# cc13x2_cc26x2 register map
File version: 2.1
CPU: CM4 r0p1, little endian, MPU, FPU, 3 interrupt priority bits
Registers are 32-bit, read-write, reset 0x0 unless marked. A register's access mark holds for its fields unless they carry their own. Offsets are from the block's base; [hi:lo] are bit positions; {n}, {i} and the like mark numbered series; 'fields as' and 'values as' point back to an identical list.

## CRYPTO — DMA Crypto Core is a low power low gate count crypto core with DMA capability and local key storage.
Base 0x40024000
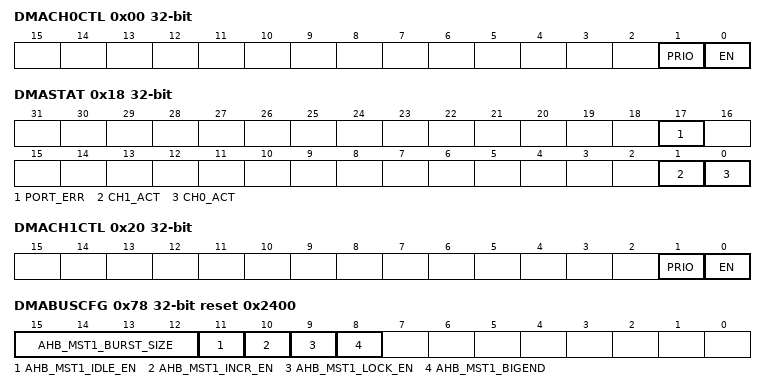
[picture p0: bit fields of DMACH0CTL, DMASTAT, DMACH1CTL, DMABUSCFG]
0x00 DMACH0CTL — Channel 0 Control his register is used for channel enabling and priority selection. When a channel is disabled, it becomes inactive only when all ongoing requests are finished.
  [1] PRIO, [0] EN
0x04 DMACH0EXTADDR — Channel 0 External Address
  [31:0] ADDR
0x0C DMACH0LEN — Channel 0 DMA Length
  [15:0] DMALEN
0x18 DMASTAT ro — DMAC Status his register provides the actual state of each DMA channel. It also reports port errors in case these were received by the master interface module during the data transfer.
  [17] PORT_ERR, [1] CH1_ACT, [0] CH0_ACT
0x1C DMASWRESET wo — DMAC Software Reset oftware reset is used to reset the DMAC to stop all transfers and clears the port error status register. After the software reset is performed, all the channels are disabled and no new requests are performed by the channels. The DMAC waits for the existing (active) requests to finish and accordingly sets the DMASTAT.
  [0] SWRES
0x20 DMACH1CTL — Channel 1 Control his register is used for channel enabling and priority selection. When a channel is disabled, it becomes inactive only when all ongoing requests are finished.
  [1] PRIO, [0] EN
0x24 DMACH1EXTADDR — Channel 1 External Address
  [31:0] ADDR
0x2C DMACH1LEN — Channel 1 DMA Length
  [15:0] DMALEN
0x78 DMABUSCFG reset 0x2400 — DMAC Master Run-time Parameters his register defines all the run-time parameters for the AHB master interface port. These parameters are required for the proper functioning of the EIP-101m AHB master adapter.
  [15:12] AHB_MST1_BURST_SIZE, [11] AHB_MST1_IDLE_EN, [10] AHB_MST1_INCR_EN, [9] AHB_MST1_LOCK_EN, [8] AHB_MST1_BIGEND
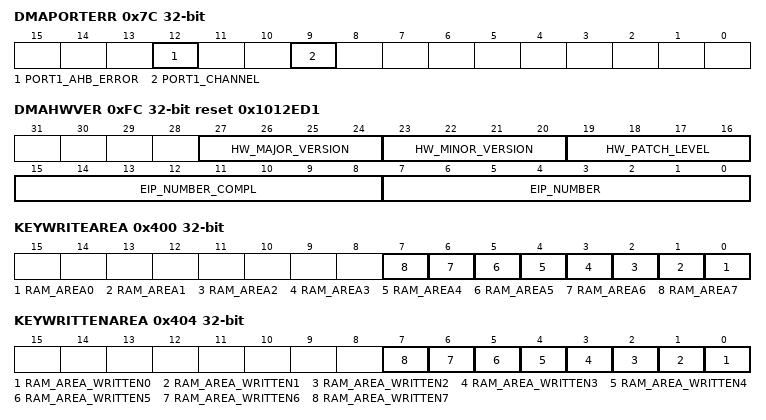
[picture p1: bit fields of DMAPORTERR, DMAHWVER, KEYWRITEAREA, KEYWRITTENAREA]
0x7C DMAPORTERR ro — DMAC Port Error Raw Status his register provides the actual status of individual port errors. It also indicates which channel is serviced by an external AHB port (which is frozen by a port error). A port error aborts operations on all serviced channels (channel enable bit is forced to 0) and prevents further transfers via that port until the error is cleared by writing to the DMASWRESET register.
  [12] PORT1_AHB_ERROR, [9] PORT1_CHANNEL
0xFC DMAHWVER ro reset 0x1012ED1 — DMAC Version his register contains an indication (or signature) of the EIP type of this DMAC, as well as the hardware version/patch numbers.
  [27:24] HW_MAJOR_VERSION, [23:20] HW_MINOR_VERSION, [19:16] HW_PATCH_LEVEL, [15:8] EIP_NUMBER_COMPL, [7:0] EIP_NUMBER
0x400 KEYWRITEAREA — Key Store Write Area his register defines where the keys should be written in the key store RAM. After writing this register, the key store module is ready to receive the keys through a DMA operation. In case the key data transfer triggered an error in the key store, the error will be available in the interrupt status register after the DMA is finished. The key store write-error is asserted when the programmed/selected area is not completely written. This error is also asserted when the DMA operation writes to ram areas that are not selected. he key store RAM is divided into 8 areas of 128 bits. 92-bit keys written in the key store RAM should start on boundaries of 256 bits. This means that writing a 192-bit key to the key store RAM must be done by writing 256 bits of data with the 64 most-significant bits set to 0. These bits are ignored by the AES engine.
  [n] RAM_AREA{n} (n=0..7)
0x404 KEYWRITTENAREA — Key Store Written Area his register shows which areas of the key store RAM contain valid written keys. hen a new key needs to be written to the key store, on a location that is already occupied by a valid key, this key area must be cleared first. This can be done by writing this register before the new key is written to the key store memory. ttempting to write to a key area that already contains a valid key is not allowed and results in an error.
  [n] RAM_AREA_WRITTEN{n} write-1-clears (n=0..7)
0x408 KEYSIZE reset 0x1 — Key Store Size his register defines the size of the keys that are written with DMA. This register should be configured before writing to the KEY_STORE_WRITE_AREA register.
  [1:0] SIZE
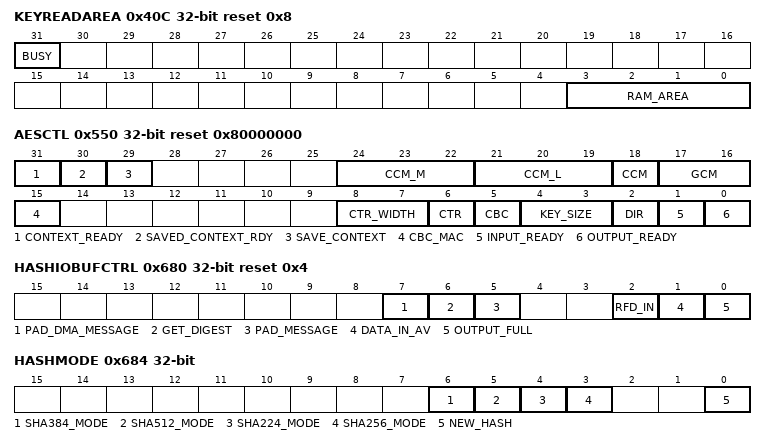
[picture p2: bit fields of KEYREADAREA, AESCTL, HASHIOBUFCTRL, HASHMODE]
0x40C KEYREADAREA reset 0x8 — Key Store Read Area his register selects the key store RAM area from where the key needs to be read that will be used for an AES operation. The operation directly starts after writing this register. When the operation is finished, the status of the key store read operation is available in the interrupt status register. Key store read error is asserted when a RAM area is selected which does not contain valid written key.
  [31] BUSY, [3:0] RAM_AREA
{0x500+4i} AESKEY2{i} (i=0..3) wo — AES_KEY2_0 / AES_GHASH_H_IN_0 econd Key / GHASH Key (internal, but clearable) he following registers are not accessible through the host for reading and writing. They are used to store internally calculated key information and intermediate results. However, when the host performs a write to the any of the respective AES_KEY2_n or AES_KEY3_n addresses, respectively the whole 128-bit AES_KEY2_n or AES_KEY3_n register is cleared to 0s. he AES_GHASH_H_IN_n registers (required for GHASH, which is part of GCM) are mapped to the AES_KEY2_n registers. The (intermediate) authentication result for GCM and CCM is stored in the AES_KEY3_n register.
  [31:0] AES_KEY2
{0x510+4i} AESKEY3{i} (i=0..3) wo — AES_KEY3_0 / AES_KEY2_4 hird Key / Second Key (internal, but clearable) he following registers are not accessible through the host for reading and writing. They are used to store internally calculated key information and intermediate results. However, when the host performs a write to the any of the respective AES_KEY2_n or AES_KEY3_n addresses, respectively the whole 128-bit AES_KEY2_n or AES_KEY3_n register is cleared to 0s. he AES_GHASH_H_IN_n registers (required for GHASH, which is part of GCM) are mapped to the AES_KEY2_n registers. The (intermediate) authentication result for GCM and CCM is stored in the AES_KEY3_n register.
  [31:0] AES_KEY3
{0x540+4i} AESIV{i} (i=0..3) — AES initialization vector registers hese registers are used to provide and read the IV from the AES engine.
  [31:0] AES_IV
0x550 AESCTL reset 0x80000000 — AES Control ES input/output buffer control and mode register his register specifies the AES mode of operation for the EIP-120t. lectronic codebook (ECB) mode is automatically selected if bits [28:5] of this register are all 0.
  [31] CONTEXT_READY, [30] SAVED_CONTEXT_RDY, [29] SAVE_CONTEXT, [24:22] CCM_M, [21:19] CCM_L, [18] CCM, [17:16] GCM, [15] CBC_MAC, [8:7] CTR_WIDTH, [6] CTR, [5] CBC, [4:3] KEY_SIZE, [2] DIR, [1] INPUT_READY, [0] OUTPUT_READY
0x554 AESDATALEN0 wo — AES Crypto Length 0 (LSW) hese registers are used to write the Length values to the EIP-120t. While processing, the length values decrement to 0. If both lengths are 0, the data stream is finished and a new context is requested. For basic AES modes (ECB, CBC, and CTR), a crypto length of 0 can be written if multiple streams need to be processed with the same key. Writing 0 length results in continued data requests until a new context is written. For the other modes (CBC-MAC, GCM, and CCM) no (new) data requests are done if the length decrements to or equals 0. t is advised to write a new length per packet. If the length registers decrement to 0, no new data is processed until a new context or length value is written. hen writing a new mode without writing the length registers, the length register values from the previous context is reused.
  [31:0] C_LENGTH
0x558 AESDATALEN1 wo — AES Crypto Length 1 (MSW) hese registers are used to write the Length values to the EIP-120t. While processing, the length values decrement to 0. If both lengths are 0, the data stream is finished and a new context is requested. For basic AES modes (ECB, CBC, and CTR), a crypto length of 0 can be written if multiple streams need to be processed with the same key. Writing 0 length results in continued data requests until a new context is written. For the other modes (CBC-MAC, GCM and CCM) no (new) data requests are done if the length decrements to or equals 0. t is advised to write a new length per packet. If the length registers decrement to 0, no new data is processed until a new context or length value is written. hen writing a new mode without writing the length registers, the length register values from the previous context is reused.
  [28:0] C_LENGTH
0x55C AESAUTHLEN wo — AES Authentication Length
  [31:0] AUTH_LENGTH
{0x560+4i} AESDATAOUT{i} ro (i=0..3) — Data Input/Output
  [31:0] DATA
0x560 AESDATAIN0 wo — AES Data Input_Output 0 he data registers are typically accessed through the DMA and not with host writes and/or reads. However, for debugging purposes the data input/output registers can be accessed via host write and read operations. The registers are used to buffer the input/output data blocks to/from the EIP-120t. ote: The data input buffer (AES_DATA_IN_n) and data output buffer (AES_DATA_OUT_n) are mapped to the same address locations. rites (both DMA and host) to these addresses load the Input Buffer while reads pull from the Output Buffer. Therefore, for write access, the data input buffer is written; for read access, the data output buffer is read. The data input buffer must be written before starting an operation. The data output buffer contains valid data on completion of an operation. Therefore, any 128-bit data block can be split over multiple 32-bit word transfers; these can be mixed with other host transfers over the external interface.
  [31:0] AES_DATA_IN_OUT
0x564 AESDATAIN1 wo — AES Data Input_Output 0 he data registers are typically accessed through the DMA and not with host writes and/or reads. However, for debugging purposes the data input/output registers can be accessed via host write and read operations. The registers are used to buffer the input/output data blocks to/from the EIP-120t. ote: The data input buffer (AES_DATA_IN_n) and data output buffer (AES_DATA_OUT_n) are mapped to the same address locations. rites (both DMA and host) to these addresses load the Input Buffer while reads pull from the Output Buffer. Therefore, for write access, the data input buffer is written; for read access, the data output buffer is read. The data input buffer must be written before starting an operation. The data output buffer contains valid data on completion of an operation. Therefore, any 128-bit data block can be split over multiple 32-bit word transfers; these can be mixed with other host transfers over the external interface.
  [31:0] AES_DATA_IN_OUT
0x568 AESDATAIN2 wo — AES Data Input_Output 2 he data registers are typically accessed via DMA and not with host writes and/or reads. However, for debugging purposes the Data Input/Output Registers can be accessed via host write and read operations. The registers are used to buffer the input/output data blocks to/from the EIP-120t. ote: The data input buffer (AES_DATA_IN_n) and data output buffer (AES_DATA_OUT_n) are mapped to the same address locations. rites (both DMA and host) to these addresses load the Input Buffer while reads pull from the Output Buffer. Therefore, for write access, the data input buffer is written; for read access, the data output buffer is read. The data input buffer must be written before starting an operation. The data output buffer contains valid data on completion of an operation. Therefore, any 128-bit data block can be split over multiple 32-bit word transfers; these can be mixed with other host transfers over the external interface.
  [31:0] AES_DATA_IN_OUT
0x56C AESDATAIN3 wo — AES Data Input_Output 3 he data registers are typically accessed via DMA and not with host writes and/or reads. However, for debugging purposes the Data Input/Output Registers can be accessed via host write and read operations. The registers are used to buffer the input/output data blocks to/from the EIP-120t. ote: The data input buffer (AES_DATA_IN_n) and data output buffer (AES_DATA_OUT_n) are mapped to the same address locations. rites (both DMA and host) to these addresses load the Input Buffer while reads pull from the Output Buffer. Therefore, for write access, the data input buffer is written; for read access, the data output buffer is read. The data input buffer must be written before starting an operation. The data output buffer contains valid data on completion of an operation. Therefore, any 128-bit data block can be split over multiple 32-bit word transfers; these can be mixed with other host transfers over the external interface.
  [31:0] AES_DATA_IN_OUT
{0x570+4i} AESTAGOUT{i} (i=0..3) ro — AES Tag Out 0 he tag registers can be accessed via DMA or directly with host reads. hese registers buffer the TAG from the EIP-120t. The registers are shared with the intermediate authentication result registers, but cannot be read until the processing is finished. While processing, a read from these registers returns 0s. If an operation does not return a TAG, reading from these registers returns an IV. If an operation returns a TAG plus an IV and both need to be read by the host, the host must first read the TAG followed by the IV. Reading these in reverse order will return the IV twice.
  [31:0] AES_TAG
{0x600+4i} HASHDATAIN{i} wo (i=1..31) — HASH Data Input {i} he data input registers should be used to provide input data to the hash module through the slave interface.
  [31:0] HASH_DATA_IN
0x680 HASHIOBUFCTRL reset 0x4 — HASH Input_Output Buffer Control his register pair shares a single address location and contains bits that control and monitor the data flow between the host and the hash engine.
  [7] PAD_DMA_MESSAGE, [6] GET_DIGEST, [5] PAD_MESSAGE, [2] RFD_IN, [1] DATA_IN_AV, [0] OUTPUT_FULL
0x684 HASHMODE wo
  [6] SHA384_MODE, [5] SHA512_MODE, [4] SHA224_MODE, [3] SHA256_MODE, [0] NEW_HASH
0x688 HASHINLENL wo — HASH Input Length LSB
  [31:0] LENGTH_IN
0x68C HASHINLENH wo — HASH Input Length MSB
  [31:0] LENGTH_IN
0x6C0 HASHDIGESTA — HASH Digest A he hash digest registers consist of eight 32-bit registers, named HASH_DIGEST_A to HASH_DIGEST_H. After processing a message, the output digest can be read from these registers. These registers can be written with an intermediate hash result for continued hash operations.
  [31:0] HASH_DIGEST
0x6C4 HASHDIGESTB — HASH Digest B he hash digest registers consist of eight 32-bit registers, named HASH_DIGEST_A to HASH_DIGEST_H. After processing a message, the output digest can be read from these registers. These registers can be written with an intermediate hash result for continued hash operations.
  [31:0] HASH_DIGEST
0x6C8 HASHDIGESTC — HASH Digest C he hash digest registers consist of eight 32-bit registers, named HASH_DIGEST_A to HASH_DIGEST_H. After processing a message, the output digest can be read from these registers. These registers can be written with an intermediate hash result for continued hash operations.
  [31:0] HASH_DIGEST
0x6CC HASHDIGESTD — HASH Digest D he hash digest registers consist of eight 32-bit registers, named HASH_DIGEST_A to HASH_DIGEST_H. After processing a message, the output digest can be read from these registers. These registers can be written with an intermediate hash result for continued hash operations.
  [31:0] HASH_DIGEST
0x6D0 HASHDIGESTE — HASH Digest E he hash digest registers consist of eight 32-bit registers, named HASH_DIGEST_A to HASH_DIGEST_H. After processing a message, the output digest can be read from these registers. These registers can be written with an intermediate hash result for continued hash operations.
  [31:0] HASH_DIGEST
0x6D4 HASHDIGESTF — HASH Digest F he hash digest registers consist of eight 32-bit registers, named HASH_DIGEST_A to HASH_DIGEST_H. After processing a message, the output digest can be read from these registers. These registers can be written with an intermediate hash result for continued hash operations.
  [31:0] HASH_DIGEST
0x6D8 HASHDIGESTG — HASH Digest G he hash digest registers consist of eight 32-bit registers, named HASH_DIGEST_A to HASH_DIGEST_H. After processing a message, the output digest can be read from these registers. These registers can be written with an intermediate hash result for continued hash operations.
  [31:0] HASH_DIGEST
0x6DC HASHDIGESTH — HASH Digest H he hash digest registers consist of eight 32-bit registers, named HASH_DIGEST_A to HASH_DIGEST_H. After processing a message, the output digest can be read from these registers. These registers can be written with an intermediate hash result for continued hash operations.
  [31:0] HASH_DIGEST
0x6E0 HASHDIGESTI — HASH Digest I he hash digest registers consist of eight 32-bit registers, named HASH_DIGEST_A to HASH_DIGEST_H. After processing a message, the output digest can be read from these registers. These registers can be written with an intermediate hash result for continued hash operations.
  [31:0] HASH_DIGEST
0x6E4 HASHDIGESTJ — HASH Digest J he hash digest registers consist of eight 32-bit registers, named HASH_DIGEST_A to HASH_DIGEST_H. After processing a message, the output digest can be read from these registers. These registers can be written with an intermediate hash result for continued hash operations.
  [31:0] HASH_DIGEST
0x6E8 HASHDIGESTK — HASH Digest K he hash digest registers consist of eight 32-bit registers, named HASH_DIGEST_A to HASH_DIGEST_H. After processing a message, the output digest can be read from these registers. These registers can be written with an intermediate hash result for continued hash operations.
  [31:0] HASH_DIGEST
0x6EC HASHDIGESTL — HASH Digest L he hash digest registers consist of eight 32-bit registers, named HASH_DIGEST_A to HASH_DIGEST_H. After processing a message, the output digest can be read from these registers. These registers can be written with an intermediate hash result for continued hash operations.
  [31:0] HASH_DIGEST
0x6F0 HASHDIGESTM — HASH Digest M he hash digest registers consist of eight 32-bit registers, named HASH_DIGEST_A to HASH_DIGEST_H. After processing a message, the output digest can be read from these registers. These registers can be written with an intermediate hash result for continued hash operations.
  [31:0] HASH_DIGEST
0x6F4 HASHDIGESTN — HASH Digest N he hash digest registers consist of eight 32-bit registers, named HASH_DIGEST_A to HASH_DIGEST_H. After processing a message, the output digest can be read from these registers. These registers can be written with an intermediate hash result for continued hash operations.
  [31:0] HASH_DIGEST
0x6F8 HASHDIGESTO — HASH Digest 0 he hash digest registers consist of eight 32-bit registers, named HASH_DIGEST_A to HASH_DIGEST_H. After processing a message, the output digest can be read from these registers. These registers can be written with an intermediate hash result for continued hash operations.
  [31:0] HASH_DIGEST
0x6FC HASHDIGESTP — HASH Digest P he hash digest registers consist of eight 32-bit registers, named HASH_DIGEST_A to HASH_DIGEST_H. After processing a message, the output digest can be read from these registers. These registers can be written with an intermediate hash result for continued hash operations.
  [31:0] HASH_DIGEST
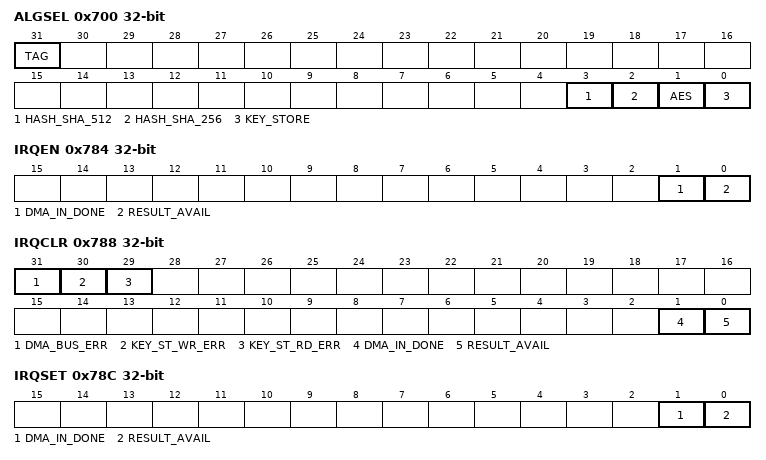
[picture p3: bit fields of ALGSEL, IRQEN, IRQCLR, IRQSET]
0x700 ALGSEL — Algorithm Select his algorithm selection register configures the internal destination of the DMA controller.
  [31] TAG, [3] HASH_SHA_512, [2] HASH_SHA_256, [1] AES, [0] KEY_STORE
0x704 DMAPROTCTL — DMA Protection Control aster PROT privileged access enable his register enables the second bit (bit [1]) of the AHB HPROT bus of the AHB master interface when a read action of key(s) is performed on the AHB master interface for writing keys into the store module.
  [0] PROT_EN
0x740 SWRESET — Software Reset
  [0] SW_RESET
0x780 IRQTYPE — Control Interrupt Configuration
  [0] LEVEL
0x784 IRQEN — Control Interrupt Enable
  [1] DMA_IN_DONE, [0] RESULT_AVAIL
0x788 IRQCLR wo — Control Interrupt Clear
  [31] DMA_BUS_ERR, [30] KEY_ST_WR_ERR, [29] KEY_ST_RD_ERR, [1] DMA_IN_DONE, [0] RESULT_AVAIL
0x78C IRQSET wo — Control Interrupt Set
  [1] DMA_IN_DONE, [0] RESULT_AVAIL
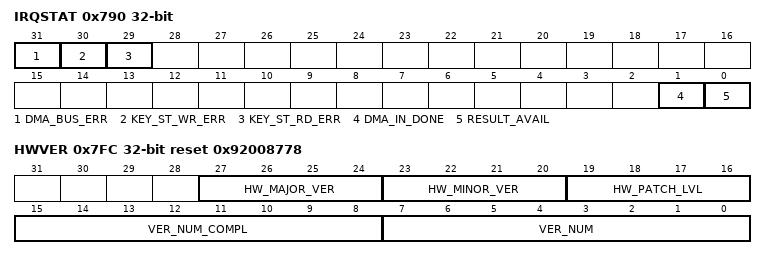
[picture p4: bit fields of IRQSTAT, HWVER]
0x790 IRQSTAT ro — Control Interrupt Status
  fields as IRQCLR
0x7FC HWVER ro reset 0x92008778 — Hardware Version
  [27:24] HW_MAJOR_VER, [23:20] HW_MINOR_VER, [19:16] HW_PATCH_LVL, [15:8] VER_NUM_COMPL, [7:0] VER_NUM
